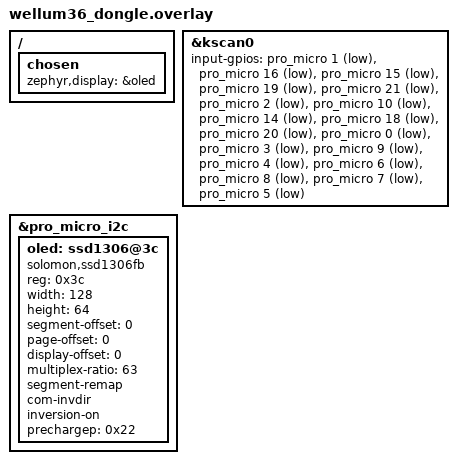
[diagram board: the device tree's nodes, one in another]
#include "wellum36.dtsi"

/ {
	chosen {
		zephyr,display = &oled;
	};
};

&kscan0 {
	input-gpios
		= <&pro_micro 1  (GPIO_ACTIVE_LOW | GPIO_PULL_UP)> // Q
		, <&pro_micro 16 (GPIO_ACTIVE_LOW | GPIO_PULL_UP)> // W
		, <&pro_micro 15 (GPIO_ACTIVE_LOW | GPIO_PULL_UP)> // E
		, <&pro_micro 19 (GPIO_ACTIVE_LOW | GPIO_PULL_UP)> // R
		, <&pro_micro 21 (GPIO_ACTIVE_LOW | GPIO_PULL_UP)> // T

		, <&pro_micro 2  (GPIO_ACTIVE_LOW | GPIO_PULL_UP)> // A
		, <&pro_micro 10 (GPIO_ACTIVE_LOW | GPIO_PULL_UP)> // S
		, <&pro_micro 14 (GPIO_ACTIVE_LOW | GPIO_PULL_UP)> // D
		, <&pro_micro 18 (GPIO_ACTIVE_LOW | GPIO_PULL_UP)> // F
		, <&pro_micro 20 (GPIO_ACTIVE_LOW | GPIO_PULL_UP)> // G

		, <&pro_micro 0  (GPIO_ACTIVE_LOW | GPIO_PULL_UP)> // Z
		, <&pro_micro 3  (GPIO_ACTIVE_LOW | GPIO_PULL_UP)> // X
		, <&pro_micro 9  (GPIO_ACTIVE_LOW | GPIO_PULL_UP)> // C
		, <&pro_micro 4  (GPIO_ACTIVE_LOW | GPIO_PULL_UP)> // V
		, <&pro_micro 6  (GPIO_ACTIVE_LOW | GPIO_PULL_UP)> // B

		, <&pro_micro 8  (GPIO_ACTIVE_LOW | GPIO_PULL_UP)> // CAPS
		, <&pro_micro 7  (GPIO_ACTIVE_LOW | GPIO_PULL_UP)> // SPACE
		, <&pro_micro 5  (GPIO_ACTIVE_LOW | GPIO_PULL_UP)> // LA_NAV
		;
};

&pro_micro_i2c {
    status = "okay";
    
    oled: ssd1306@3c {
        compatible = "solomon,ssd1306fb";
        reg = <0x3c>;
        width = <128>;
        height = <64>;
        segment-offset = <0>;
        page-offset = <0>;
        display-offset = <0>;
        multiplex-ratio = <63>;
        segment-remap;
        com-invdir;
        inversion-on;
        prechargep = <0x22>;
    };
}; 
